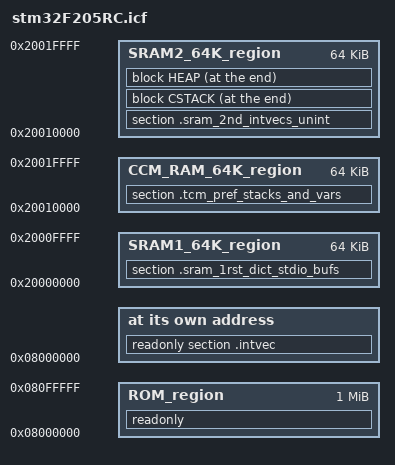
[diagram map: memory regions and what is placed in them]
/*###ICF### Section handled by ICF editor, don't touch! ****/
/*-Editor annotation file-*/
/* IcfEditorFile="$TOOLKIT_DIR$\config\ide\IcfEditor\cortex_v1_0.xml" */
/*-Specials-*/
define symbol __ICFEDIT_intvec_start__ = 0x08000000;
/*-Memory Regions-*/
define symbol __ICFEDIT_region_ROM_start__ = 0x08000000;
define symbol __ICFEDIT_region_ROM_end__   = 0x080FFFFF; /* 1,048,575 */
define symbol __ICFEDIT_region_RAM_start__ = 0x20000000;
define symbol __ICFEDIT_region_RAM_end__   = 0x2001FFFF; /* 131,071k 1/8th of the meg */
/*-Sizes-*/
define symbol __ICFEDIT_size_cstack__ = 0x2000;
define symbol __ICFEDIT_size_heap__   = 0x2000;
/**** End of ICF editor section. ###ICF###*/

define symbol __region_SRAM1_start__ = 0x20000000;
define symbol __region_SRAM1_end__   = 0x2000FFFF; /* 65,535k */
define symbol __region_SRAM2_start__ = 0x20010000;
define symbol __region_SRAM2_end__   = 0x2001FFFF; /* 2nd 65k */

define memory mem with size = 4G;
define region ROM_region   = mem:[from __ICFEDIT_region_ROM_start__   to __ICFEDIT_region_ROM_end__];
//define region CCM_RAM_64K_region   = mem:[from __region_SRAM2_start__   to __region_SRAM2_end__];
define region CCM_RAM_64K_region   = mem:[from __region_SRAM2_start__   to __region_SRAM2_end__];
define region SRAM1_64K_region  = mem:[from __region_SRAM1_start__   to __region_SRAM1_end__];
define region SRAM2_64K_region  = mem:[from __region_SRAM2_start__   to __region_SRAM2_end__];

define block CSTACK    with alignment = 8, size = __ICFEDIT_size_cstack__   { };
define block HEAP      with alignment = 8, size = __ICFEDIT_size_heap__     { };

//initialize by copy { section .noinint }; // , readwrite

//do not initialize  { readwrite, section .sram_1rst_dict_stdio_bufs, section .sram_2nd_intvecs_unint }; // , readwrite
do not initialize  { readwrite, section .sram_1rst_dict_stdio_bufs, section .sram_2nd_intvecs_unint, section .tcm_pref_stacks_and_vars }; // , readwrite

place at address mem:__ICFEDIT_intvec_start__ { readonly section .intvec };

place in ROM_region   { readonly };
place in CCM_RAM_64K_region   { section .tcm_pref_stacks_and_vars };
place in SRAM1_64K_region  { section .sram_1rst_dict_stdio_bufs };
place in SRAM2_64K_region  { section .sram_2nd_intvecs_unint };
//place in SRAM2_64K_region  { section .sram_2nd_intvecs_unint, section .ccm_64k };
// modified end of to include ccm here
//place in SRAM2_64k_region  ( section .ccm_64k );
//place at end of SRAM2_64K_region  { section .ccm_64k, block CSTACK, block HEAP };
//place at end of SRAM2_64K_region  { section .sram_2nd_intvecs_unint, section .ccm_64k, block CSTACK, block HEAP };

place at end of SRAM2_64K_region  { block CSTACK, block HEAP };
